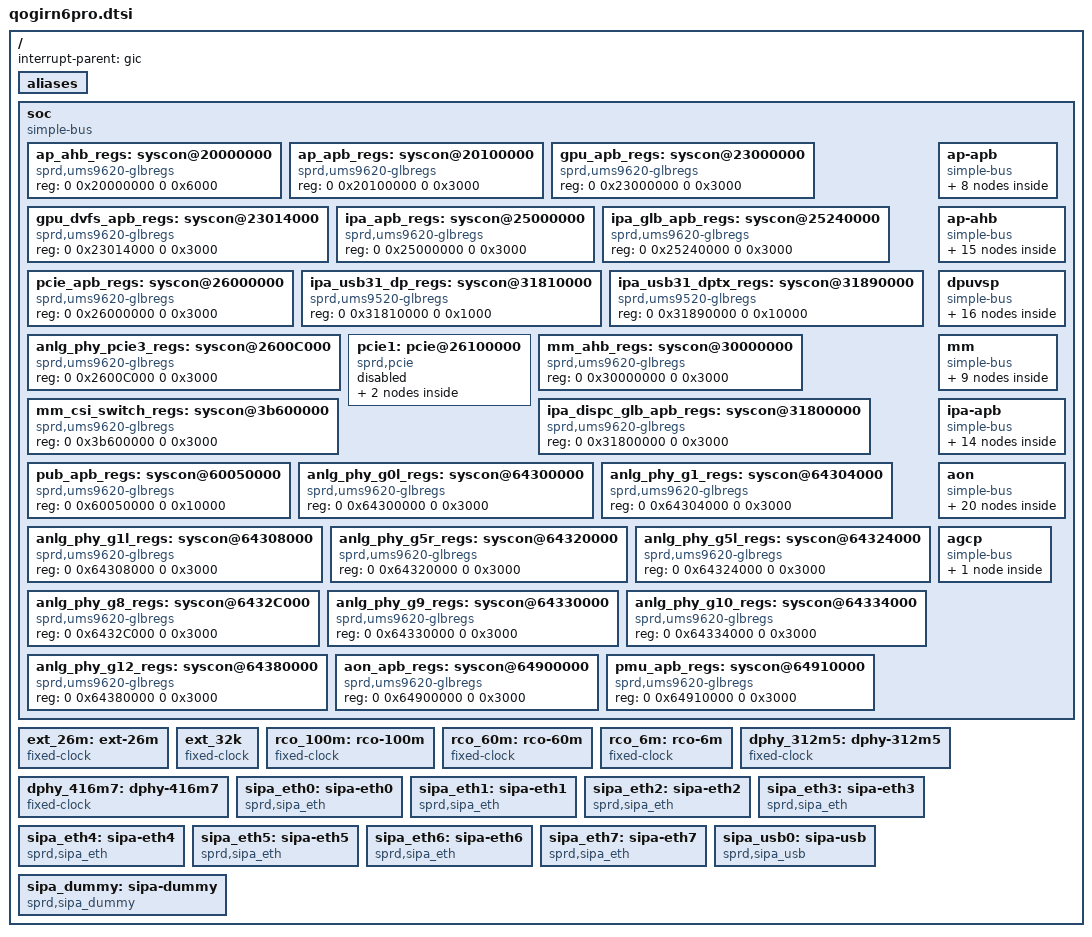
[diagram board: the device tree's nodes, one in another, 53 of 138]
// SPDX-License-Identifier: GPL-2.0-only
/*
 * Unisoc Qogirl6pro platform DTS file
 *
 * Copyright (C) 2020, Unisoc Inc.
 */

#include <dt-bindings/clock/sprd,ums9620-clk.h>
#include <dt-bindings/soc/sprd,qogirn6pro-regs.h>
#include <dt-bindings/soc/sprd,qogirn6pro-mask.h>
#include <dt-bindings/debug/busmonitor/busmonitor.h>

/ {
	interrupt-parent = <&gic>;
	#address-cells = <2>;
	#size-cells = <2>;

	aliases {
		i2c0 = &i2c0;
		i2c1 = &i2c1;
		i2c2 = &i2c2;
		i2c3 = &i2c3;
		i2c4 = &i2c4;
		i2c5 = &i2c5;
		i2c6 = &i2c6;
		i2c7 = &i2c7;
		i2c8 = &i2c8;
		i2c9 = &i2c9;
		spi0 = &spi0;
		spi1 = &spi1;
		spi2 = &spi2;
		spi4 = &adi_bus;
		eth0 = &sipa_eth0;
		eth1 = &sipa_eth1;
		eth2 = &sipa_eth2;
		eth3 = &sipa_eth3;
		eth4 = &sipa_eth4;
		eth5 = &sipa_eth5;
		eth6 = &sipa_eth6;
		eth7 = &sipa_eth7;
	};

	soc: soc {
		compatible = "simple-bus";
		#address-cells = <2>;
		#size-cells = <2>;
		ranges;

		ap_ahb_regs: syscon@20000000 {
			compatible = "sprd,ums9620-glbregs", "syscon";
			#syscon-cells = <2>;
			reg = <0 0x20000000 0 0x6000>;
		};

		ap_apb_regs: syscon@20100000 {
			compatible = "sprd,ums9620-glbregs", "syscon";
			#syscon-cells = <2>;
			reg = <0 0x20100000 0 0x3000>;
		};

		gpu_apb_regs: syscon@23000000 {
			compatible = "sprd,ums9620-glbregs", "syscon";
			#syscon-cells = <2>;
			reg = <0 0x23000000 0 0x3000>;
		};

		gpu_dvfs_apb_regs: syscon@23014000 {
			compatible = "sprd,ums9620-glbregs", "syscon";
			#syscon-cells = <2>;
			reg = <0 0x23014000 0 0x3000>;
		};

		ipa_apb_regs: syscon@25000000 {
			compatible = "sprd,ums9620-glbregs", "syscon";
			#syscon-cells = <2>;
			reg = <0 0x25000000 0 0x3000>;
		};

		ipa_glb_apb_regs: syscon@25240000 {
			compatible = "sprd,ums9620-glbregs", "syscon";
			#syscon-cells = <2>;
			reg = <0 0x25240000 0 0x3000>;
		};

		pcie_apb_regs: syscon@26000000 {
			compatible = "sprd,ums9620-glbregs", "syscon";
			#syscon-cells = <2>;
			reg = <0 0x26000000 0 0x3000>;
		};

		ipa_usb31_dp_regs: syscon@31810000 {
			compatible = "sprd,ums9520-glbregs", "syscon";
			#syscon-cells = <2>;
			reg = <0 0x31810000 0 0x1000>;
		};

		ipa_usb31_dptx_regs: syscon@31890000 {
			compatible = "sprd,ums9520-glbregs", "syscon";
			#syscon-cells = <2>;
			reg = <0 0x31890000 0 0x10000>;
		};

		anlg_phy_pcie3_regs: syscon@2600C000 {
			compatible = "sprd,ums9620-glbregs", "syscon";
			#syscon-cells = <2>;
			reg = <0 0x2600C000 0 0x3000>;
		};

		pcie1: pcie@26100000 {
			compatible = "sprd,pcie", "snps,dw-pcie";
			reg = <0x0 0x26100000 0x0 0x100000>,
			      <0x8 0x87ffe000 0x0 0x100000>;
			reg-names = "dbi", "config";
			#address-cells = <3>;
			#size-cells = <2>;
			device_type = "pci";
			ranges = <0x01000000 0x0 0x00000000 0x8 0x87fee000 0x0 0x00010000
				  0x03000000 0x0 0x10000000 0x8 0x80000000 0x0 0x07fee000>;
			bus-range = <16 31>;
			num-lanes = <1>;
			num-vectors = <256>;
			num-viewport = <8>;
			pcie-wakeup-gpios = <&eic_async 12
					     GPIO_ACTIVE_HIGH>;
			status = "disabled";
			dummy@0 {
				label = "msi_int";
				interrupt-parent = <&gic>;
				#interrupt-cells = <3>;
				interrupts = <GIC_SPI 82
					      IRQ_TYPE_LEVEL_HIGH>;
			};
			dummy@1 {
				label = "aer_int";
				interrupt-parent = <&gic>;
				#interrupt-cells = <3>;
				interrupts = <GIC_SPI 83
					      IRQ_TYPE_LEVEL_HIGH>;
			};
		};

		mm_ahb_regs: syscon@30000000 {
			compatible = "sprd,ums9620-glbregs", "syscon";
			#syscon-cells = <2>;
			reg = <0 0x30000000 0 0x3000>;
		};

		ipa_dispc_glb_apb_regs: syscon@31800000 {
			compatible = "sprd,ums9620-glbregs", "syscon";
			#syscon-cells = <2>;
			reg = <0 0x31800000 0 0x3000>;
		};

		mm_csi_switch_regs: syscon@3b600000 {
			compatible = "sprd,ums9620-glbregs", "syscon";
			#syscon-cells = <2>;
			reg = <0 0x3b600000 0 0x3000>;
		};

		pub_apb_regs: syscon@60050000 {
			compatible = "sprd,ums9620-glbregs", "syscon";
			#syscon-cells = <2>;
			reg = <0 0x60050000 0 0x10000>;
		};

		anlg_phy_g0l_regs: syscon@64300000 {
			compatible = "sprd,ums9620-glbregs", "syscon";
			#syscon-cells = <2>;
			reg = <0 0x64300000 0 0x3000>;
		};

		anlg_phy_g1_regs: syscon@64304000 {
			compatible = "sprd,ums9620-glbregs", "syscon";
			#syscon-cells = <2>;
			reg = <0 0x64304000 0 0x3000>;
		};

		anlg_phy_g1l_regs: syscon@64308000 {
			compatible = "sprd,ums9620-glbregs", "syscon";
			#syscon-cells = <2>;
			reg = <0 0x64308000 0 0x3000>;
		};

		anlg_phy_g5r_regs: syscon@64320000 {
			compatible = "sprd,ums9620-glbregs", "syscon";
			#syscon-cells = <2>;
			reg = <0 0x64320000 0 0x3000>;
		};

		anlg_phy_g5l_regs: syscon@64324000 {
			compatible = "sprd,ums9620-glbregs", "syscon";
			#syscon-cells = <2>;
			reg = <0 0x64324000 0 0x3000>;
		};

		anlg_phy_g8_regs: syscon@6432C000 {
			compatible = "sprd,ums9620-glbregs", "syscon";
			#syscon-cells = <2>;
			reg = <0 0x6432C000 0 0x3000>;
		};

		anlg_phy_g9_regs: syscon@64330000 {
			compatible = "sprd,ums9620-glbregs", "syscon";
			#syscon-cells = <2>;
			reg = <0 0x64330000 0 0x3000>;
		};

		anlg_phy_g10_regs: syscon@64334000 {
			compatible = "sprd,ums9620-glbregs", "syscon";
			#syscon-cells = <2>;
			reg = <0 0x64334000 0 0x3000>;
		};

		anlg_phy_g12_regs: syscon@64380000 {
			compatible = "sprd,ums9620-glbregs", "syscon";
			#syscon-cells = <2>;
			reg = <0 0x64380000 0 0x3000>;
		};

		aon_apb_regs: syscon@64900000 {
			compatible = "sprd,ums9620-glbregs", "syscon";
			#syscon-cells = <2>;
			reg = <0 0x64900000 0 0x3000>;
		};

		pmu_apb_regs: syscon@64910000 {
			compatible = "sprd,ums9620-glbregs", "syscon";
			#syscon-cells = <2>;
			reg = <0 0x64910000 0 0x3000>;
		};

		ap-apb {
			compatible = "simple-bus";
			#address-cells = <1>;
			#size-cells = <1>;
			ranges = <0 0 0x20200000 0x100000>;

			uart0: serial@0 {
				compatible = "sprd,ums9620-uart",
					     "sprd,sc9836-uart";
				reg = <0 0x100>;
				interrupts = <GIC_SPI 196 IRQ_TYPE_LEVEL_HIGH>;
				clock-names = "enable", "uart", "source";
				clocks = <&apapb_gate CLK_UART0_EB>,
					<&ap_clk CLK_AP_UART0>, <&ext_26m>;
				status = "disabled";
			};

			uart1: serial@10000 {
				compatible = "sprd,ums9620-uart",
					     "sprd,sc9836-uart";
				reg = <0x10000 0x100>;
				interrupts = <GIC_SPI 195 IRQ_TYPE_LEVEL_HIGH>;
				clock-names = "enable", "uart", "source";
				clocks = <&apapb_gate CLK_UART1_EB>,
					<&ap_clk CLK_AP_UART1>, <&ext_26m>;
				status = "disabled";
			};

			uart2: serial@20000 {
				compatible = "sprd,ums9620-uart",
					     "sprd,sc9836-uart";
				reg = <0x20000 0x100>;
				interrupts = <GIC_SPI 167 IRQ_TYPE_LEVEL_HIGH>;
				clock-names = "enable", "uart", "source";
				clocks = <&apapb_gate CLK_UART2_EB>,
					<&ap_clk CLK_AP_UART2>, <&ext_26m>;
				status = "disabled";
			};

			uart3: serial@30000 {
				compatible = "sprd,ums9620-uart",
					     "sprd,sc9836-uart";
				reg = <0x30000 0x100>;
				interrupts = <GIC_SPI 166 IRQ_TYPE_LEVEL_HIGH>;
				clock-names = "enable", "uart", "source";
				clocks = <&apapb_gate CLK_UART3_EB>,
					<&ap_clk CLK_AP_UART3>, <&ext_26m>;
				status = "disabled";
			};

			spi0: spi@60000{
				compatible = "sprd,ums9620-spi";
				reg = <0x60000 0x1000>;
				interrupts = <GIC_SPI 199 IRQ_TYPE_LEVEL_HIGH>;
				#address-cells = <1>;
				#size-cells = <0>;
				status = "disabled";
			};

			spi1: spi@70000{
				compatible = "sprd,ums9620-spi";
				reg = <0x70000 0x1000>;
				interrupts = <GIC_SPI 198 IRQ_TYPE_LEVEL_HIGH>;
				#address-cells = <1>;
				#size-cells = <0>;
				status = "disabled";
			};

			spi2: spi@80000{
				compatible = "sprd,ums9620-spi";
				reg = <0x80000 0x1000>;
				interrupts = <GIC_SPI 197 IRQ_TYPE_LEVEL_HIGH>;
				#address-cells = <1>;
				#size-cells = <0>;
				status = "disabled";
			};

			crypto_engine_rng: rng@e0000 {
				compatible = "sprd,sprd-trng";
				reg = <0xe0000 0x10000>;
				clock-names = "ce-pub-eb", "ap-ce-clk",
							  "source";
				clocks = <&apapb_gate CLK_CE_PUB_EB>,
					   <&ap_clk CLK_AP_CE>,
					   <&g5l_pll CLK_TGPLL_256M>;
			};
		};

		ap-ahb {
			compatible = "simple-bus";
			#address-cells = <1>;
			#size-cells = <1>;
			ranges = <0 0 0x20000000 0x22d0040>;

			ap_dma: dma-controller@20000 {
				compatible = "sprd,qogirn6pro-dma";
				reg = <0x20000 0x4000>;
				interrupts = <GIC_SPI 219 IRQ_TYPE_LEVEL_HIGH>;
				#dma-cells = <1>;
				#dma-channels = <28>;
				clock-names = "enable";
				clocks = <&apahb_gate CLK_DMA_PUB_EB>;
			};

			ufs: ufs@2000000 {
				compatible  = "sprd,ufshc";
				interrupts = <GIC_SPI 159 IRQ_TYPE_LEVEL_HIGH>;
				vcc-supply = <&vddemmccore>;
				clock-names = "ufs_eb",
					      "ufs_cfg_eb",
					      "ufs_hclk",
					      "ufs_hclk_source";
				clocks = <&apahb_gate CLK_UFS_EB>,
					 <&apahb_gate CLK_UFS_CFG_EB>,
					 <&aonapb_clk CLK_UFS_AON>,
					 <&g5l_pll CLK_TGPLL_256M>;
				freq-table-hz = <0 0>,
						<0 0>,
						<0 0>,
						<0 0>;
				syscons =
					<&ap_ahb_regs REG_AP_AHB_AHB_RST
					  MASK_AP_AHB_UFS_SOFT_RST>,
					<&aon_apb_regs REG_AON_APB_UFSDEV_REG
					  MASK_AON_APB_UFSDEV_SOFT_RST>,
					<&anlg_phy_g12_regs 0x0c 0x01>;
				syscon-names = "ap_ahb_ufs_rst",
					       "aon_apb_ufs_rst",
					       "phy_sram_init_done";
				status = "okay";
			};

			sdio3: sdio@2200000 {
				compatible = "sprd,sdhc-r11p1";
				reg = <0x2200000 0x1000>;
				interrupts = <GIC_SPI 217 IRQ_TYPE_LEVEL_HIGH>;
				status = "disabled";
			};

			sdio0: sdio@2210000 {
				compatible = "sprd,sdhc-r11p1";
				reg = <0x2210000 0x1000>;
				interrupts = <GIC_SPI 203 IRQ_TYPE_LEVEL_HIGH>;
				status = "disabled";
				syscons = <&aon_apb_regs REG_AON_APB_SDIO0_CTRL_REG
					MASK_AON_APB_SDIO0_EMMC_CARD_PRESENT_32K>,
					<&aon_apb_regs REG_AON_APB_SDIO0_CTRL_REG
					MASK_AON_APB_SDIO0_EMMC_CARD_PROTECT_32K>,
					<&aon_apb_regs REG_AON_APB_SDIO0_CTRL_REG
					MASK_AON_APB_SDIO0_EMMC_CARDDET_DBNC_EN_32K>,
					<&aon_apb_regs REG_AON_APB_SDIO0_CTRL_REG
					MASK_AON_APB_SDIO0_EMMC_CARDDET_DBNC_THD_32K>;
				syscon-names = "sd_detect_pol",
					       "sd_hotplug_protect_en",
					       "sd_hotplug_debounce_en",
					       "sd_hotplug_debounce_cn";
			};

			sdio1: sdio@2220000 {
				compatible = "sprd,sdhc-r11p1";
				reg = <0x2220000 0x1000>;
				interrupts = <GIC_SPI 202 IRQ_TYPE_LEVEL_HIGH>;
				status = "disabled";
			};

			i2c0: i2c@2240000 {
				compatible = "sprd,qogirn6pro-i2c";
				reg = <0x2240000 0x100>;
				interrupts = <GIC_SPI 216 IRQ_TYPE_LEVEL_HIGH>;
				clock-frequency = <400000>;
				#address-cells = <1>;
				#size-cells = <0>;
				status = "disabled";
			};

			i2c1: i2c@2250000 {
				compatible = "sprd,qogirn6pro-i2c";
				reg = <0x2250000 0x100>;
				interrupts = <GIC_SPI 215 IRQ_TYPE_LEVEL_HIGH>;
				clock-frequency = <400000>;
				#address-cells = <1>;
				#size-cells = <0>;
				status = "disabled";
			};

			i2c2: i2c@2260000 {
				compatible = "sprd,qogirn6pro-i2c";
				reg = <0x2260000 0x100>;
				interrupts = <GIC_SPI 214 IRQ_TYPE_LEVEL_HIGH>;
				clock-frequency = <400000>;
				#address-cells = <1>;
				#size-cells = <0>;
				status = "disabled";
			};

			i2c3: i2c@2270000 {
				compatible = "sprd,qogirn6pro-i2c";
				reg = <0x2270000 0x100>;
				interrupts = <GIC_SPI 213 IRQ_TYPE_LEVEL_HIGH>;
				clock-frequency = <400000>;
				#address-cells = <1>;
				#size-cells = <0>;
				status = "disabled";
			};

			i2c4: i2c@2280000 {
				compatible = "sprd,qogirn6pro-i2c";
				reg = <0x2280000 0x100>;
				interrupts = <GIC_SPI 212 IRQ_TYPE_LEVEL_HIGH>;
				clock-frequency = <400000>;
				#address-cells = <1>;
				#size-cells = <0>;
				status = "disabled";
			};

			i2c5: i2c@2290000 {
				compatible = "sprd,qogirn6pro-i2c";
				reg = <0x2290000 0x100>;
				interrupts = <GIC_SPI 211 IRQ_TYPE_LEVEL_HIGH>;
				clock-frequency = <400000>;
				#address-cells = <1>;
				#size-cells = <0>;
				status = "disabled";
			};

			i2c6: i2c@22a0000 {
				compatible = "sprd,qogirn6pro-i2c";
				reg = <0x22a0000 0x100>;
				interrupts = <GIC_SPI 210 IRQ_TYPE_LEVEL_HIGH>;
				clock-frequency = <400000>;
				#address-cells = <1>;
				#size-cells = <0>;
				status = "disabled";
			};

			i2c7: i2c@22b0000 {
				compatible = "sprd,qogirn6pro-i2c";
				reg = <0x22b0000 0x100>;
				interrupts = <GIC_SPI 209 IRQ_TYPE_LEVEL_HIGH>;
				clock-frequency = <400000>;
				#address-cells = <1>;
				#size-cells = <0>;
				status = "disabled";
			};

			i2c8: i2c@22c0000 {
				compatible = "sprd,qogirn6pro-i2c";
				reg = <0x22c0000 0x100>;
				interrupts = <GIC_SPI 208 IRQ_TYPE_LEVEL_HIGH>;
				clock-frequency = <400000>;
				#address-cells = <1>;
				#size-cells = <0>;
				status = "disabled";
			};

			i2c9: i2c@22d0000 {
				compatible = "sprd,qogirn6pro-i2c";
				reg = <0x22d0000 0x100>;
				interrupts = <GIC_SPI 207 IRQ_TYPE_LEVEL_HIGH>;
				clock-frequency = <400000>;
				#address-cells = <1>;
				#size-cells = <0>;
				status = "disabled";
			};
		};

		dpuvsp {
			compatible = "simple-bus";
			#address-cells = <2>;
			#size-cells = <2>;
			ranges;

			dpu: dpu@31000000 {
				compatible = "sprd,display-processor";
				reg = <0x0 0x31000000 0x0 0x3000>;
				/*syscons = <&ap_ahb_regs REG_AP_AHB_RF_AHB_RST
				MASK_AP_AHB_RF_DISPC_SOFT_RST>,
				<&ap_ahb_regs REG_AP_AHB_RF_AP_QOS2
				(MASK_AP_AHB_RF_ARQOS_THRESHHOLD_DISP |
				MASK_AP_AHB_RF_AWQOS_THRESHHOLD_DISP)>;
				syscon-names = "reset", "qos";
				*/
				interrupts = <GIC_SPI 152 IRQ_TYPE_LEVEL_HIGH>;
				status = "disabled";
				iommus = <&iommu_dispc>;

				dma-coherent;
				sprd,ip = "dpu-r6p0";
				sprd,soc = "qogirn6pro";

				dpu_port: port {
					dpu_out: endpoint {
						remote-endpoint = <&dsi_in>;
					};
				};
			};

			iommu_dispc: iommu@31001800 {
				compatible = "sprd,iommuvau-dispc";
				reg = <0x0 0x31001800 0x0 0x80>;
				sprd,iova-base = <0x30000000>;
				sprd,iova-size = <0x10000000>;
				reg_name = "mmu_reg";
				status = "disabled";
				#iommu-cells = <0>;
			};

			iommu_gsp: iommu@31100000 {
				compatible = "sprd,iommuvaul5p-gsp";
				reg = <0x0 0x31100000 0x0 0x1000>,
				      <0x0 0x31101000 0x0 0x80>;
				sprd,iova-base = <0x30000000>;
				sprd,iova-size = <0x10000000>;
				reg_name = "mmu_interrupt_reg","mmu_reg";
				status = "disabled";
				#iommu-cells = <0>;
			};

			dsi: dsi@31300000 {
				compatible = "sprd,dsi-host";
				reg = <0x0 0x31300000 0x0 0x1000>;
				/*syscons = <&ap_ahb_regs REG_AP_AHB_RF_AHB_RST
				MASK_AP_AHB_RF_DSI_SOFT_RST>;
				syscon-names = "reset";
				interrupts = <GIC_SPI 158 IRQ_TYPE_LEVEL_HIGH>,
				<GIC_SPI 157 IRQ_TYPE_LEVEL_HIGH>;
				*/
				status = "disabled";

				sprd,ip = "sprd,dsi-ctrl", "r3p1";
				sprd,soc = "qogirn6pro";

				ports {
					#address-cells = <1>;
					#size-cells = <0>;

					port@0 {
						reg = <0>;
						dsi_out: endpoint {
							remote-endpoint = <&dphy_in>;
						};
					};

					port@1 {
						reg = <1>;
						dsi_in: endpoint {
							remote-endpoint = <&dpu_out>;
						};
					};
				};
			};

			dphy: dphy {
				compatible = "sprd,dsi-phy";
				#address-cells = <1>;
				#size-cells = <0>;
				reg = <0x0 0x31300000 0x0 0x1000>;
				/*syscons = <&ap_ahb_regs
				REG_AP_AHB_RF_MISC_CKG_EN
				(MASK_AP_AHB_RF_DPHY_REF_CKG_EN |
				MASK_AP_AHB_RF_DPHY_CFG_CKG_EN)>,
				<&pmu_apb_regs
				REG_PMU_APB_RF_ANALOG_PHY_PD_CFG
				MASK_PMU_APB_RF_DSI_PD_REG>;
				syscon-names = "enable", "power";*/
				status = "disabled";
				sprd,ip = "sprd,megacores-sharkl5";
				sprd,soc = "qogirn6pro";
				sprd,mipi-drive-capability = <7>;
				/* output port */
				port@0 {
					reg = <0>;
					dphy_out: endpoint {
					remote-endpoint = <&panel_in>;
					};
				};
				/* input port*/
				port@1 {
					reg = <1>;
					dphy_in: endpoint {
						remote-endpoint = <&dsi_out>;
					};
				};
			};
		};

		mm {
			compatible = "simple-bus";
			#address-cells = <2>;
			#size-cells = <2>;
			ranges;

			mm_domain: mm_domain {
				compatible = "sprd,mm-domain";
				syscon-names = "force_shutdown",
					"shutdown_en",
					"camera_power_state",
					"isp_force_shutdown",
					"isp_shutdown_en",
					"isp_power_state",
					"dcam_force_shutdown",
					"dcam_shutdown_en",
					"dcam_power_state";
				syscons =
				<&pmu_apb_regs
				REG_PMU_APB_PD_CAMERA_CFG_0
				MASK_PMU_APB_PD_CAMERA_FORCE_SHUTDOWN>,
				<&pmu_apb_regs
				REG_PMU_APB_PD_CAMERA_CFG_0
				MASK_PMU_APB_PD_CAMERA_AUTO_SHUTDOWN_EN>,
				<&pmu_apb_regs
				REG_PMU_APB_PWR_STATUS_DBG_6
				MASK_PMU_APB_PD_CAMERA_STATE>,
				<&pmu_apb_regs
				REG_PMU_APB_PD_ISP_BLK_CFG_0
				MASK_PMU_APB_PD_ISP_BLK_FORCE_SHUTDOWN>,
				<&pmu_apb_regs
				REG_PMU_APB_PD_ISP_BLK_CFG_0
				MASK_PMU_APB_PD_ISP_BLK_AUTO_SHUTDOWN_EN>,
				<&pmu_apb_regs
				REG_PMU_APB_PWR_STATUS_DBG_7
				MASK_PMU_APB_PD_ISP_BLK_STATE>,
				<&pmu_apb_regs
				REG_PMU_APB_PD_DCAM_BLK_CFG_0
				MASK_PMU_APB_PD_DCAM_BLK_FORCE_SHUTDOWN>,
				<&pmu_apb_regs
				REG_PMU_APB_PD_DCAM_BLK_CFG_0
				MASK_PMU_APB_PD_DCAM_BLK_AUTO_SHUTDOWN_EN>,
				<&pmu_apb_regs
				REG_PMU_APB_PWR_STATUS_DBG_7
				MASK_PMU_APB_PD_DCAM_BLK_STATE>;
				clock-names = "clk_mm_eb",
					"clk_ckg_en",
					"clk_mm_mtx_data_en",
					"clk_mm_mtx_data",
					"clk_mm_mtx_parent";
				clocks = <&aonapb_gate CLK_MM_EB>,
					<&mm_gate CLK_CKG_EN>,
					<&mm_gate CLK_MM_MTX_DATA_EN>,
					<&mm_clk CLK_MM_MTX_DATA>,
					<&g5l_pll CLK_TGPLL_512M>;
			};

			dcam: dcam@3e000000 {
				compatible = "sprd,qogirn6pro-cam";
				reg = <0 0x3e000000 0 0x10000>,
					<0 0x3e010000 0 0x10000>,
					<0 0x3e100000 0 0x80>,
					<0 0x3e104000 0 0x80>,
					<0 0x3e030000 0 0xB0>,
					<0 0x3e108000 0 0x50>,
					<0 0x3e038000 0 0x40>;
				reg-names = "dcam0_reg",
						"dcam1_reg",
						"dcam2_reg",
						"dcam3_reg",
						"dcam01_axi_ctrl_reg",
						"dcam23_axi_ctrl_reg",
						"fmcu_ctrl_reg";
				interrupts = <GIC_SPI 108 IRQ_TYPE_LEVEL_HIGH>,
					<GIC_SPI 107 IRQ_TYPE_LEVEL_HIGH>,
					<GIC_SPI 110 IRQ_TYPE_LEVEL_HIGH>,
					<GIC_SPI 109 IRQ_TYPE_LEVEL_HIGH>;
				interrupt-names = "dcam0",
							"dcam1",
							"dcam2",
							"dcam3";
				syscons = <&mm_ahb_regs REG_MM_AHB_DCAM_BLK_SOFT_RST
					MASK_MM_AHB_DCAM0_1_ALL_SOFT_RST>,
					<&mm_ahb_regs REG_MM_AHB_DCAM_BLK_SOFT_RST
					MASK_MM_AHB_DCAM2_3_ALL_SOFT_RST>,
					<&mm_ahb_regs REG_MM_AHB_DCAM_BLK_SOFT_RST
					MASK_MM_AHB_DCAM0_SOFT_RST>,
					<&mm_ahb_regs REG_MM_AHB_DCAM_BLK_SOFT_RST
					MASK_MM_AHB_DCAM1_SOFT_RST>,
					<&mm_ahb_regs REG_MM_AHB_DCAM_BLK_SOFT_RST
					MASK_MM_AHB_DCAM2_SOFT_RST>,
					<&mm_ahb_regs REG_MM_AHB_DCAM_BLK_SOFT_RST
					MASK_MM_AHB_DCAM3_SOFT_RST>;
				syscon-names = "dcam01_all_reset",
						"dcam23_all_reset",
						"dcam0_reset",
						"dcam1_reset",
						"dcam2_reset",
						"dcam3_reset";

				clock-names = "dcam_eb",
					"dcam_blk_cfg_en",
					"dcam_lite_eb",
					"dcam_tck_en",
					"dcam_mtx_en",
					"dcam_lite_mtx_en",
					"dcam_clk",
					"dcam_clk_parent",
					"dcam_lite_clk",
					"dcam_lite_clk_parent",
					"dcam_axi_clk",
					"dcam_axi_clk_parent",
					"dcam_lite_axi_clk",
					"dcam_lite_axi_clk_parent",
					"dcam_mtx_clk",
					"dcam_mtx_clk_parent",
					"dcam_blk_cfg_clk",
					"dcam_blk_cfg_clk_parent";
				clocks = <&mm_gate CLK_DCAM_IF_EN>,
					<&mm_gate CLK_DCAM_BLK_CFG_EN>,
					<&mm_gate CLK_DCAM_IF_LITE_EN>,
					<&mm_gate CLK_DCAM_TCK_EN>,
					<&mm_gate CLK_DCAM_MTX_EN>,
					<&mm_gate CLK_DCAM_LITE_MTX_EN>,
					<&mm_clk CLK_DCAM0_1>,
					<&g5l_pll CLK_TGPLL_512M>,
					<&mm_clk CLK_DCAM2_3>,
					<&g5l_pll CLK_TGPLL_256M>,
					<&mm_clk CLK_DCAM0_1_AXI>,
					<&g5l_pll CLK_TGPLL_512M>,
					<&mm_clk CLK_DCAM2_3_AXI>,
					<&g5l_pll CLK_TGPLL_256M>,
					<&mm_clk CLK_DCAM_MTX>,
					<&g5l_pll CLK_TGPLL_512M>,
					<&mm_clk CLK_DCAM_BLK_CFG>,
					<&g5l_pll CLK_TGPLL_128M>;

				sprd,cam-ahb-syscon = <&mm_ahb_regs>;
				sprd,csi-switch = <&mm_csi_switch_regs>;
				sprd,isp = <&isp>;
				sprd,dcam-count = <4>;
				sprd,dcam-superzoom = <2>;
				sprd,project-id = <4>;
				iommus = <&iommu_dcam>;
				status = "okay";
			};

			iommu_dcam: iommu@3e03f000 {
				compatible = "sprd,iommuvau-dcam";
				reg = <0x0 0x3e03f000 0x0 0xB0>;
				sprd,iova-base = <0x40000000>;
				sprd,iova-size = <0xc0000000>;
				reg_name = "mmu_reg";
				status = "okay";
				#iommu-cells = <0>;
			};

			isp: isp@3a000000 {
				compatible = "sprd,isp";
				reg = <0 0x3A000000 0 0x100000>;
				interrupts = <GIC_SPI 240 IRQ_TYPE_LEVEL_HIGH>,
					<GIC_SPI 241 IRQ_TYPE_LEVEL_HIGH>,
					<GIC_SPI 238 IRQ_TYPE_LEVEL_HIGH>;
				interrupts_name = "ispch0", "ispch1", "dec";
				syscons = <&mm_ahb_regs REG_MM_AHB_ISP_BLK_SOFT_RST
						MASK_MM_AHB_ISP_VAU_SOFT_RST>,
						<&mm_ahb_regs REG_MM_AHB_ISP_BLK_SOFT_RST
						MASK_MM_AHB_ISP_ALL_SOFT_RST>,
						<&mm_ahb_regs REG_MM_AHB_ISP_BLK_SOFT_RST
						MASK_MM_AHB_ISP_SOFT_RST>;
				syscon-names = "isp_vau_reset",
							     "isp_ahb_reset",
							     "reset";
				clock-names = "isp_eb",
						"isp_mtx_en",
						"isp_blk_cfg_en",
						"isp_tck_en",
						"isp_clk",
						"isp_clk_153m6",
						"isp_clk_256m",
						"isp_clk_307m2",
						"isp_clk_409m6",
						"isp_clk_512m",
						"isp_clk_parent";
				clocks = <&mm_gate CLK_ISP_EN>,
						<&mm_gate CLK_ISP_MTX_EN>,
						<&mm_gate CLK_ISP_BLK_CFG_EN>,
						<&mm_gate CLK_ISP_TCK_EN>,
						<&mm_clk CLK_ISP>,
						<&g5l_pll CLK_TGPLL_153M6>,
						<&g5l_pll CLK_TGPLL_256M>,
						<&g5l_pll CLK_TGPLL_307M2>,
						<&g5l_pll CLK_V4NRPLL_409M6>,
						<&g5l_pll CLK_TGPLL_512M>,
						<&g5l_pll CLK_TGPLL_512M>;
				sprd,cam-ahb-syscon = <&mm_ahb_regs>;
				sprd,isp-count = <1>;
				iommus = <&iommu_isp>;
				status = "okay";
			};

			iommu_isp: iommu@3a0ff000 {
				compatible = "sprd,iommuvau-isp";
				reg = <0x0 0x3a0ff000 0x0 0xb0>;
				sprd,iova-base = <0x40000000>;
				sprd,iova-size = <0xc0000000>;
				reg_name = "mmu_reg";
				status = "okay";
				#iommu-cells = <0>;
			};

			fd: fd@3C000000 {
				compatible = "sprd,fd";
				reg = <0 0x3C000000 0 0x100000>;
				interrupts = <GIC_SPI 117 IRQ_TYPE_LEVEL_HIGH>;
				interrupts_name = "fdraw";
				clock-names = "fd_eb",
					"fd_axi_eb", /* no need read, TBC */
					"isp_mtx_en",
					"isp_blk_cfg_en",
					"fd_clk",
					"fd_clk_parent";
				clocks = <&mm_gate CLK_FD_EN>,
					<&mm_gate CLK_ISP_EN>,
					<&mm_gate CLK_ISP_MTX_EN>,
					<&mm_gate CLK_ISP_BLK_CFG_EN>,
					<&mm_clk CLK_FD>,
					<&g5l_pll CLK_TGPLL_384M>;
				syscons = <&mm_ahb_regs REG_MM_AHB_ISP_BLOCK_EN
					MASK_MM_AHB_FD_EN>,
					<&mm_ahb_regs REG_MM_AHB_ISP_BLK_SOFT_RST
					MASK_MM_AHB_FD_SOFT_RST>,
					<&mm_ahb_regs REG_MM_AHB_ISP_BLK_SOFT_RST
					MASK_MM_AHB_FD_ALL_SOFT_RST>,
					<&mm_ahb_regs REG_MM_AHB_MM_LP_DISABLE
					MASK_MM_AHB_MM_LPC_DISABLE>,
					<&mm_ahb_regs REG_MM_AHB_MM_SYS_EN
					MASK_MM_AHB_DVFS_EN>;
				syscon-names = "fd_eb", "fd_rst", "fd_save_rst",
					"fd_lpc", "fd_dvfs_eb";
				/*fd_qos = <&fd_qos>;*/
				status = "okay";
			};

			iommu_fd: iommu@3C000000 {
				compatible = "sprd,iommuvau-fd";
				reg = <0 0x3C000110 0 0x80>;
				sprd,iova-base = <0x40000000>;
				sprd,iova-size = <0x10000000>;
				reg_name = "mmu_reg";
				status = "okay";
				#iommu-cells = <0>;
			};

			cpp: cpp@38000000 {
				compatible = "sprd,cpp";
				reg = <0 0x38000000 0 0x1000>;
				interrupts = <GIC_SPI 112 IRQ_TYPE_LEVEL_HIGH>;
				clock-names = "cpp_eb",
					"cpp_axi_eb", /* no need read, TBC */
					"isp_mtx_en",
					"isp_blk_cfg_en",
					"cpp_clk",
					"cpp_clk_parent";
				clocks = <&mm_gate CLK_CPP_EN>,
					<&mm_gate CLK_ISP_EN>,
					<&mm_gate CLK_ISP_MTX_EN>,
					<&mm_gate CLK_ISP_BLK_CFG_EN>,
					<&mm_clk CLK_CPP>,
					<&g5l_pll CLK_TGPLL_384M>;
				sprd,cam-ahb-syscon = <&mm_ahb_regs>;
				/*cpp_qos = <&cpp_qos>;*/
				status = "okay";
			};

			iommu_cpp: iommu@38000200 {
				compatible = "sprd,iommuvau-cpp";
				reg = <0x0 0x38000200 0x0 0x80>;
				sprd,iova-base = <0x40000000>;
				sprd,iova-size = <0x20000000>;
				reg_name = "mmu_reg";
				status = "okay";
				#iommu-cells = <0>;
			};
		};

		ipa-apb {
			compatible = "simple-bus";
			#address-cells = <2>;
			#size-cells = <2>;
			ranges;

			sipa: sipa@25220000 {
				compatible = "sprd,qogirn6pro-sipa";
				reg = <0 0x25220000 0 0x00002000>;
				reg-names = "ipa-base";
				interrupts = <GIC_SPI 137 IRQ_TYPE_LEVEL_HIGH>,
					<GIC_SPI 136 IRQ_TYPE_LEVEL_HIGH>,
					<GIC_SPI 135 IRQ_TYPE_LEVEL_HIGH>,
					<GIC_SPI 134 IRQ_TYPE_LEVEL_HIGH>,
					<GIC_SPI 133 IRQ_TYPE_LEVEL_HIGH>,
					<GIC_SPI 132 IRQ_TYPE_LEVEL_HIGH>,
					<GIC_SPI 131 IRQ_TYPE_LEVEL_HIGH>,
					<GIC_SPI 130 IRQ_TYPE_LEVEL_HIGH>,
					<GIC_SPI 138 IRQ_TYPE_LEVEL_HIGH>;
				interrupt-names = "ipa_irq0", "ipa_irq1",
					"ipa_irq2", "ipa_irq3",
					"ipa_irq4", "ipa_irq5",
					"ipa_irq6", "ipa_irq7",
					"ipa_general";
				syscons = <&ipa_glb_apb_regs
					REG_IPA_GLB_APB_IPA_IP_EB
					MASK_IPA_GLB_APB_IPA_EB>,
					<&ipa_glb_apb_regs
					REG_IPA_GLB_APB_IPA_IP_EB
					MASK_IPA_GLB_APB_TFT_EB>;
				syscon-names = "enable-ipa", "enable-tft";

				sprd,sipa-bypass-mode = <0>;

				power-domains = <&pd_ipa_sys>;

				fifo-names = "sprd,usb-ul", "sprd,usb-dl",
					"sprd,wifi-ul", "sprd,wifi-dl";
				fifo-sizes = <0 2048 0 2048>, <0 2048 0 2048>,
					<0 128 0 128>, <0 128 0 128>;
			};

			ipa_delegate: sipa-dele {
				compatible = "sprd,qogirn6pro-sipa-delegate";

				sprd,ul-fifo-depth = <4096>;
				sprd,dl-fifo-depth = <4096>;
			};

			dpu1: dpu1@31880000 {
				compatible = "sprd,display-processor1";
				reg = <0x0 0x31880000 0x0 0x3000>;
				syscons = <&ipa_dispc_glb_apb_regs REG_DISPC1_GLB_APB_APB_RST
					  MASK_DISPC1_GLB_APB_DPU1_SOFT_RST>,
					  <&pmu_apb_regs REG_PMU_APB_PD_DPU_DP_CFG_0
					   MASK_PMU_APB_PD_DPU_DP_FORCE_SHUTDOWN>;
				syscon-names = "reset", "force-shutdown";
				interrupts = <GIC_SPI 120 IRQ_TYPE_LEVEL_HIGH>;
				status = "disable";
				iommus = <&iommu_dispc1>;

				sprd,dev-id = <1>;
				dma-coherent;

				sprd,ip = "dpu-lite-r3p0";
				sprd,soc = "qogirn6pro1";
				sprd,initial-stop-state;

				power-domains = <&pd_ipa_sys>;
				clock-names = "clk_src_128m",
						"clk_src_192m",
						"clk_src_256m",
						"clk_pixelpll",
						"clk_src_307m2",
						"clk_src_384m",
						"clk_src_512m",
						"clk_dpu_core",
						"clk_dpu_dpi",
						"clk_ipa_apb_dispc1_eb";
				clocks = <&g5l_pll CLK_TGPLL_128M>,
					  <&g5l_pll CLK_TGPLL_192M>,
					  <&g5l_pll CLK_TGPLL_256M>,
					  <&g5r_pll CLK_PIXELPLL>,
					  <&g5l_pll CLK_TGPLL_307M2>,
					  <&g5l_pll CLK_TGPLL_384M>,
					  <&g5l_pll CLK_TGPLL_512M>,
					  <&ipa_clk CLK_IPA_DPU>,
					  <&ipa_clk CLK_IPA_DPI>,
					  <&ipadispc_gate CLK_IPA_DPU1_EB>;

				dpu1_port: port {
					dpu1_out: endpoint {
						remote-endpoint = <&dptx_in>;
					};
				};
			};

			iommu_dispc1: iommu@31880000 {
				compatible = "sprd,iommuvau-dispc1";
				reg = <0x0 0x31880800 0x0 0x80>;
				sprd,iova-base = <0x40000000>;
				sprd,iova-size = <0x10000000>;
				reg_name = "mmu_reg";
				status = "disable";
				#iommu-cells = <0>;
			};

			dptx: dptx@31890000 {
				compatible = "sprd,dptx";
				reg = <0x0 0x31890000 0x0 0x70000>;
				status = "disable";
				interrupts = <GIC_SPI 123 IRQ_TYPE_LEVEL_HIGH>;

				sprd,soc = "qogirn6pro1";

				power-domains = <&pd_ipa_sys>;
				clock-names = "clk_ipa_apb_dptx_eb";
				clocks = <&ipadispc_gate CLK_IPA_DPTX_EB>;

				ports {
					#address-cells = <1>;
					#size-cells = <0>;

					port@1 {
						reg = <1>;
						dptx_in: endpoint {
						remote-endpoint = <&dpu1_out>;
						};
					};
				};
			};

			usb3: usb3@25100000 {
				compatible = "sprd,qogirn6pro-dwc3";
				reg = <0 0x25100000 0 0x100000>;
				status = "disabled";
				#address-cells = <2>;
				#size-cells = <2>;
				ranges;

				clocks = <&ipaapb_gate CLK_USB_EB>,
					<&ipaapb_gate CLK_USB_REF_EB>,
					<&ipaapb_gate CLK_USB_SUSPEND_EB>,
					<&ipa_clk CLK_USB_REF>,
					<&ext_32k>;
				clock-names = "core_clk", "ref_clk", "susp_clk",
					"ipa_usb_ref", "ipa_usb_ref_default";
				usb-phy = <&ssphy>, <&ssphy>;
				power-domains = <&pd_ipa_sys>;

				dwc3@25100000 {
					compatible = "snps,dwc3";
					reg = <0 0x25100000 0 0x100000>;
					interrupts = <GIC_SPI 142 IRQ_TYPE_LEVEL_HIGH>;
					interrupt-names = "irq";
					usb-phy = <&ssphy>, <&ssphy>;
					usb-pam = <&pamu3>;
					phy_type = "utmi";
					dr_mode = "peripheral";
					snps,usb3-u1u2-disable;
					snps,dis_u3_susphy_quirk;
					snps,dis_u2_susphy_quirk;
					snps,overlap_check_quirk;
					snps,ep_out_aligned_size_quirk;
					snps,disconnect_event_quirk;
					snps,usb3_slow_suspend;
					snps,host_suspend_capable;
				};
			};

			pamu3: pamu3@25210000 {
				compatible = "sprd,qogirn6pro-pamu3";
				clocks = <&ipaapb_gate CLK_PAM_USB_EB>;
				clock-names = "pamu3_clk";
				power-domains = <&pd_ipa_sys>;
				reg = <0 0x25210000 0 0x10000>,
					<0 0x25100000 0 0x100000>;
				reg-names = "pamu3_glb_regs",
					"dwc3_core_regs";
			};

			ssphy: ssphy@25310000 {
				compatible = "sprd,qogirn6pro-ssphy";
				reg = <0 0x25310000 0 0x10000>;
				reg-names = "phy_glb_regs";
				power-domains = <&pd_ipa_sys>;
				sprd,syscon-aon-apb = <&aon_apb_regs>;
				sprd,syscon-ana-g0l = <&anlg_phy_g0l_regs>;
				sprd,syscon-ipa-apb = <&ipa_apb_regs>;
				sprd,syscon-ipa-dispc1-glb-apb = <&ipa_dispc_glb_apb_regs>;
				sprd,syscon-ipa-usb31-dp = <&ipa_usb31_dp_regs>;
				sprd,syscon-ipa-usb31-dptx = <&ipa_usb31_dptx_regs>;
				sprd,vdd-voltage = <3300000>;
				status = "disabled";

			};


		};

		aon {
			compatible = "simple-bus";
			#address-cells = <1>;
			#size-cells = <1>;
			ranges = <0 0 0x64000000 0x1016000>;

			ap_efuse: efuse@160000 {
				compatible = "sprd,qogirn6pro-efuse";
				reg = <0x160000 0x10000>;
				clock-names = "enable";
				hwlocks = <&hwlock 8>;
				clocks = <&aonapb_gate CLK_EFUSE_EB>;
			};

			pwms: pwm@30000 {
				compatible = "sprd,qogirn6pro-pwm";
				reg = <0x30000 0x10000>;
				clock-names = "clk_parent",
					"clk_pwm0", "clk_pwm0_eb",
					"clk_pwm1", "clk_pwm1_eb",
					"clk_pwm2", "clk_pwm2_eb",
					"clk_pwm3", "clk_pwm3_eb";
				clocks = <&ext_26m>,
					<&aonapb_clk CLK_PWM0>,
					<&aonapb_gate CLK_PWM0_EB>,
					<&aonapb_clk CLK_PWM1>,
					<&aonapb_gate CLK_PWM1_EB>,
					<&aonapb_clk CLK_PWM2>,
					<&aonapb_gate CLK_PWM2_EB>,
					<&aonapb_clk CLK_PWM3>,
					<&aonapb_gate CLK_PWM3_EB>;
				#pwm-cells = <2>;
			};

			ap_gpio: gpio@170000 {
				compatible = "sprd,qogirn6pro-gpio","sprd,qogirl6-gpio";
				reg = <0x170000 0x10000>;
				gpio-controller;
				#gpio-cells = <2>;
				interrupt-controller;
				#interrupt-cells = <2>;
				interrupts = <GIC_SPI 40 IRQ_TYPE_LEVEL_HIGH>;
			};

			eic_debounce: gpio@200000 {
				compatible = "sprd,qogirn6pro-eic-debounce","sprd,qogirl6-eic-debounce";
				reg = <0x200000 0x80>,
				      <0x210000 0x80>,
				      <0x220000 0x80>,
				      <0x230000 0x80>,
				      <0x240000 0x80>,
				      <0x250000 0x80>;
				gpio-controller;
				#gpio-cells = <2>;
				interrupt-controller;
				#interrupt-cells = <2>;
				interrupts = <GIC_SPI 24 IRQ_TYPE_LEVEL_HIGH>;
			};

			eic_latch: gpio@200080 {
				compatible = "sprd,qogirn6pro-eic-latch","sprd,qogirl6-eic-latch";
				reg = <0x200080 0x20>,
				      <0x210080 0x20>,
				      <0x220080 0x20>,
				      <0x230080 0x20>,
				      <0x240080 0x20>,
				      <0x250080 0x20>;
				gpio-controller;
				#gpio-cells = <2>;
				interrupt-controller;
				#interrupt-cells = <2>;
				interrupts = <GIC_SPI 24 IRQ_TYPE_LEVEL_HIGH>;
			};

			eic_async: gpio@2000a0 {
				compatible = "sprd,qogirn6pro-eic-async","sprd,qogirl6-eic-async";
				reg = <0x2000a0 0x20>,
				      <0x2100a0 0x20>,
				      <0x2200a0 0x20>,
				      <0x2300a0 0x20>,
				      <0x2400a0 0x20>,
				      <0x2500a0 0x20>;
				gpio-controller;
				#gpio-cells = <2>;
				interrupt-controller;
				#interrupt-cells = <2>;
				interrupts = <GIC_SPI 24 IRQ_TYPE_LEVEL_HIGH>;
			};

			eic_sync: gpio@2000c0 {
				compatible = "sprd,qogirn6pro-eic-sync","sprd,qogirl6-eic-sync";
				reg = <0x2000c0 0x20>,
				      <0x2100c0 0x20>,
				      <0x2200c0 0x20>,
				      <0x2300c0 0x20>,
				      <0x2400c0 0x20>,
				      <0x2500c0 0x20>;
				gpio-controller;
				#gpio-cells = <2>;
				interrupt-controller;
				#interrupt-cells = <2>;
				interrupts = <GIC_SPI 24 IRQ_TYPE_LEVEL_HIGH>;
			};

			aon_mailbox: mailbox@600000 {
				compatible = "sprd,mailbox";
				reg = <0x600000 0x40000>;
				syscons = <&aon_apb_regs 0x4 0x4>;
				syscon-names = "clk";
				interrupts = <GIC_SPI 45 IRQ_TYPE_LEVEL_HIGH>,
					     <GIC_SPI 44 IRQ_TYPE_LEVEL_HIGH>,
					     <GIC_SPI 43 IRQ_TYPE_LEVEL_HIGH>;
				sprd,sensor = <6>;
				sprd,core-cnt = <7>;
				sprd,version = <0x200>;
			};

			pd_ipa_sys: sipa-sys {
				compatible =
				"sprd,qogirn6pro-ipa-sys-power-domain";
				syscons = <&pmu_apb_regs
					REG_PMU_APB_PD_IPA_CFG_0
					MASK_PMU_APB_PD_IPA_AUTO_SHUTDOWN_EN>,
					<&pmu_apb_regs
					REG_PMU_APB_IPA_DSLP_ENA
					MASK_PMU_APB_IPA_DSLP_ENA>,
					<&pmu_apb_regs
					REG_PMU_APB_PWR_STATUS_DBG_22
					MASK_PMU_APB_PD_IPA_STATE>,
					<&pmu_apb_regs
					REG_PMU_APB_FORCE_LIGHT_SLEEP_CFG_0
					MASK_PMU_APB_IPA_FORCE_LIGHT_SLEEP>,
					<&pmu_apb_regs
					REG_PMU_APB_LIGHT_SLEEP_ENABLE
					MASK_PMU_APB_IPA_LSLP_ENA>,
					<&pmu_apb_regs
					REG_PMU_APB_SMART_LIGHT_SLEEP_ENABLE
					MASK_PMU_APB_IPA_SMART_LSLP_ENA>,
					<&aon_apb_regs
					REG_AON_APB_IPA_ACCESS_CFG
					MASK_AON_APB_AON_TO_IPA_ACCESS_EN>;
				syscon-names =
					"ipa-sys-autoshutdownen",
					"ipa-sys-dslpen",
					"ipa-sys-state",
					"ipa-sys-forcelslp",
					"ipa-sys-lslpen",
					"ipa-sys-smartlslpen",
					"ipa-sys-accessen";
				reg-size = <7>;

				#power-domain-cells = <0>;

				clocks = <&ipadispc_gate CLK_IPA_CKG_EB>,
					<&ipa_clk CLK_IPA_AXI>,
					<&g5l_pll CLK_V4NRPLL_409M6>,
					<&ext_26m>;
				clock-names = "clk_ipa_ckg_eb", "ipa_core",
					"ipa_core_source", "ipa_core_default";
			};

			timer@40000 {
				compatible = "sprd,qogirn6pro-timer",
						"sprd,sc9860-timer";
				reg = <0x40000 0x20>;
				interrupts = <GIC_SPI 47 IRQ_TYPE_LEVEL_HIGH>;
				clocks = <&ext_32k>;
			};

			timer@40020 {
				compatible = "sprd,qogirn6pro-suspend-timer",
						"sprd,sc9860-suspend-timer";
				reg = <0x40020 0x20>;
				clocks = <&ext_32k>;
			};

			watchdog@1e0000 {
				compatible = "sprd,wdt-r2p0-fiq";
				reg = <0x1e0000 0x10000>;
				interrupts = <GIC_SPI 26 IRQ_TYPE_LEVEL_HIGH>;
				timeout-sec = <12>;
				clock-names = "enable", "rtc_enable";
				clocks = <&aonapb_gate CLK_APCPU_WDG_EB>,
				       <&aonapb_gate CLK_AC_WDG_RTC_EB>;
			};

			pin_controller: pinctrl@2e0000 {
				compatible = "sprd,qogirl6pro-pinctrl";
				reg = <0x2e0000 0x10000>;
			};

			adi_bus: spi@400000 {
				compatible = "sprd,qogirn6pro-adi";
				reg = <0x400000 0x100000>;
			};

			djtag: djtag@64570000 {
				compatible = "sprd,djtag";
				status = "okay";
				reg = <0x570000 0x1000>;
				syscon-names = "soft_rst";
				syscons = <&aon_apb_regs REG_AON_APB_APB_RST3
					MASK_AON_APB_DJTAG_SOFT_RST>;
				clock-names = "enable", "tck";
				clocks = <&aonapb_gate CLK_DJTAG_EB>,
					<&aonapb_gate CLK_DJTAG_TCK_EN>;
				hwlocks = <&hwlock 10>;
				hwlock-names = "djtag";

				#address-cells = <1>;
				#size-cells = <0>;

				aon-busmonitor@7{
					compatible = "sprd,qogirn6pro-busmonitor";
					interrupts = <GIC_SPI 7 IRQ_TYPE_LEVEL_HIGH>;
					reg = <0x7>;
					sprd,bm-num = <11>;
					sprd,bm-name =
						"AP", "IPA", "AUDCP", "PSCP",
						"PHYCP", "SP_CMSTAR", "DEBUG_SYS",
						"USB_OTG", "APCPU", "CH_CMSTAR",
						"PUB_SYS";
					sprd,bm-type =
						<AXI>, <AXI>, <AXI>, <AXI>,
						<AXI>, <AXI>, <AXI>, <AXI>,
						<AXI>, <AXI>, <AXI>;
					sprd,bm-dap = <0>, <1>, <2>, <3>,
						<4>, <5>, <6>, <7>, <8>,
						<9>, <11>;
					sprd,bm-config =
						<DISABLE MON_WRITE MON_INSIDE>,
						<DISABLE MON_WRITE MON_INSIDE>,
						<DISABLE MON_WRITE MON_INSIDE>,
						<DISABLE MON_WRITE MON_INSIDE>,
						<DISABLE MON_WRITE MON_INSIDE>,
						<DISABLE MON_WRITE MON_INSIDE>,
						<DISABLE MON_WRITE MON_INSIDE>,
						<DISABLE MON_WRITE MON_INSIDE>,
						<DISABLE MON_WRITE MON_INSIDE>,
						<DISABLE MON_WRITE MON_INSIDE>,
						<DISABLE MON_WRITE MON_INSIDE>;
					sprd,bm-id =
						<DISABLE 0 AXIID>,
						<DISABLE 0 AXIID>,
						<DISABLE 0 AXIID>,
						<DISABLE 0 AXIID>,
						<DISABLE 0 AXIID>,
						<DISABLE 0 AXIID>,
						<DISABLE 0 AXIID>,
						<DISABLE 0 AXIID>,
						<DISABLE 0 AXIID>,
						<DISABLE 0 AXIID>,
						<DISABLE 0 AXIID>;
					sprd,bm-ranges =
						<0 0>,
						<0 0>,
						<0 0>,
						<0 0>,
						<0 0>,
						<0 0>,
						<0 0>,
						<0 0>,
						<0 0>,
						<0 0>,
						<0 0>;
				};

			};

			hsphy: hsphy@300000 {
				compatible = "sprd,qogirn6pro-phy";
				reg = <0x300000 0x10000>;
				sprd,syscon-enable = <&aon_apb_regs>;
				sprd,syscon-anag0 = <&anlg_phy_g0l_regs>;
				sprd,vdd-voltage = <3300000>;
				#phy-cells = <0>;
			};

			usb: usb@a00000 {
				compatible = "sprd,qogirn6pro-musb";
				reg = <0xa00000 0x2000>;
				interrupts = <GIC_SPI 8 IRQ_TYPE_LEVEL_HIGH>;
				interrupt-names = "mc";
				clocks = <&ext_26m>;
				clock-names = "core_clk";
				usb-phy = <&hsphy>;
				phy-names = "usb";
				dr-mode = "peripheral";
				multipoint = "true";
				wakeup-source;
			};

			hwlock: hwspinlock@a10000 {
				compatible = "sprd,hwspinlock-r3p0";
				reg = <0xa10000 0x10000>;
				#hwlock-cells = <1>;
				clock-names = "enable";
				clocks = <&aonapb_gate CLK_SPLK_EB>;
			};

			apb_bm: apb-busmonitor@64580000 {
				compatible = "sprd,apb-busmonitor";
				reg = <0x580000 0x1000>;
				interrupts = <GIC_SPI 15 IRQ_TYPE_LEVEL_HIGH>;
				sprd,target-addr = <0 0>;
				sprd,target-data = <0 0>;
			 };
		};

		agcp {
			compatible = "simple-bus";
			#address-cells = <2>;
			#size-cells = <2>;
			ranges;

			agcp_dma: dma-controller@56650000 {
				compatible = "sprd,qogirn6pro-dma";
				reg = <0 0x56650000 0 0x4000>;
				interrupts = <GIC_SPI 55 IRQ_TYPE_LEVEL_HIGH>;
				#dma-cells = <1>;
				#dma-channels = <32>;
				clock-names = "enable", "ashb_eb";
				clocks = <&audcpglb_gate CLK_AUDCP_DMA_AP_EB>,
					<&audcpglb_gate CLK_AUDCP_DMA_AP_ASHB_EB>;
			};
		};
	};

	ext_26m: ext-26m {
		compatible = "fixed-clock";
		#clock-cells = <0>;
		clock-frequency = <26000000>;
		clock-output-names = "ext-26m";
	};

	ext_32k: ext_32k {
		compatible = "fixed-clock";
		#clock-cells = <0>;
		clock-frequency = <32768>;
		clock-output-names = "ext-32k";
	};

	rco_100m: rco-100m {
		compatible = "fixed-clock";
		#clock-cells = <0>;
		clock-frequency = <100000000>;
		clock-output-names = "rco-100m";
	};

	rco_60m: rco-60m {
		compatible = "fixed-clock";
		#clock-cells = <0>;
		clock-frequency = <60000000>;
		clock-output-names = "rco-60m";
	};

	rco_6m: rco-6m {
		compatible = "fixed-clock";
		#clock-cells = <0>;
		clock-frequency = <6000000>;
		clock-output-names = "rco-6m";
	};

	dphy_312m5: dphy-312m5 {
		compatible = "fixed-clock";
		#clock-cells = <0>;
		clock-frequency = <312500000>;
		clock-output-names = "dphy-312m5";
	};

	dphy_416m7: dphy-416m7 {
		compatible = "fixed-clock";
		#clock-cells = <0>;
		clock-frequency = <416700000>;
		clock-output-names = "dphy-416m7";
	};

	sipa_eth0: sipa-eth0 {
		compatible = "sprd,sipa_eth";
		sprd,netid = <1>;
		sprd,term-type = <0x6>;
	};

	sipa_eth1: sipa-eth1 {
		compatible = "sprd,sipa_eth";
		sprd,netid = <2>;
		sprd,term-type = <0x6>;
	};

	sipa_eth2: sipa-eth2 {
		compatible = "sprd,sipa_eth";
		sprd,netid = <3>;
		sprd,term-type = <0x6>;
	};

	sipa_eth3: sipa-eth3 {
		compatible = "sprd,sipa_eth";
		sprd,netid = <4>;
		sprd,term-type = <0x6>;
	};

	sipa_eth4: sipa-eth4 {
		compatible = "sprd,sipa_eth";
		sprd,netid = <5>;
		sprd,term-type = <0x6>;
	};

	sipa_eth5: sipa-eth5 {
		compatible = "sprd,sipa_eth";
		sprd,netid = <6>;
		sprd,term-type = <0x6>;
	};

	sipa_eth6: sipa-eth6 {
		compatible = "sprd,sipa_eth";
		sprd,netid = <7>;
		sprd,term-type = <0x6>;
	};

	sipa_eth7: sipa-eth7 {
		compatible = "sprd,sipa_eth";
		sprd,netid = <8>;
		sprd,term-type = <0x6>;
	};

	sipa_usb0: sipa-usb {
		compatible = "sprd,sipa_usb";
		sprd,netid = <0>;
		sprd,term-type = <0x1>;
	};

	sipa_dummy: sipa-dummy {
		compatible = "sprd,sipa_dummy";
	};
};

